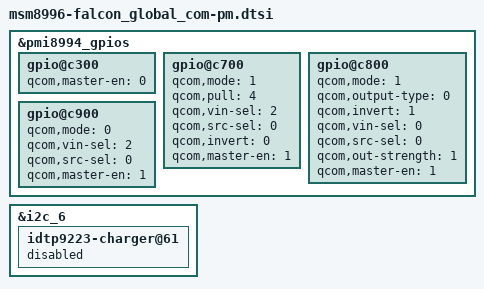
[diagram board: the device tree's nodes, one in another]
/* Copyright (c) 2015, The Linux Foundation. All rights reserved.
 *
 * This program is free software; you can redistribute it and/or modify
 * it under the terms of the GNU General Public License version 2 and
 * only version 2 as published by the Free Software Foundation.
 *
 * This program is distributed in the hope that it will be useful,
 * but WITHOUT ANY WARRANTY; without even the implied warranty of
 * MERCHANTABILITY or FITNESS FOR A PARTICULAR PURPOSE.  See the
 * GNU General Public License for more details.
 */

#include "../msm8996-falcon-common/msm8996-falcon-common-pm.dtsi"

&pmi8994_gpios {
	gpio@c300 { /* GPIO 4 - NC */
		qcom,master-en = <0>;		/* Disable GPIO */
		status = "okay";
	};
	
	gpio@c700 {
	  qcom,mode = <1>;
	  qcom,pull = <4>;
	  qcom,vin-sel = <2>;
	  qcom,src-sel = <0>;
	  qcom,invert = <0>;
	  qcom,master-en = <1>;
	  status = "okay";
	 };

	gpio@c800 {
	  qcom,mode = <1>;
	  qcom,output-type = <0>;
	  qcom,invert = <1>;
	  qcom,vin-sel = <0>;
	  qcom,src-sel = <0>;
	  qcom,out-strength = <1>;
	  qcom,master-en = <1>;
	  status = "okay";
	 };

	 gpio@c900 {
	  qcom,mode = <0>;
	  qcom,vin-sel = <2>;
	  qcom,src-sel = <0>;
	  qcom,master-en = <1>;
	  status = "okay";
	 };

};

&i2c_6 {
        idtp9223-charger@61 {
                status = "disabled";
        };
};
